# DAC_DAC_50260000h register map
Vendor: Texas Instruments
Peripheral module from a debugger description file (folder AM263X).
Registers are 16-bit, read-write, reset 0x0 unless marked. A register's access mark holds for its fields unless they carry their own. Offsets are as the file gives them; lines under a group give offsets from that group; [hi:lo] are bit positions; {n}, {i} and the like mark numbered series; 'fields as' and 'values as' point back to an identical list; <NAME> marks a mode.

## DAC
0x00 DAC_DACREV ro — DAC Revision Register.
  [7:0] REV — DAC Revision
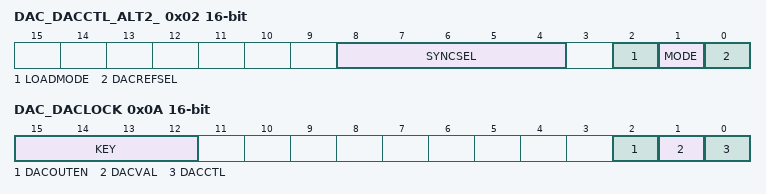
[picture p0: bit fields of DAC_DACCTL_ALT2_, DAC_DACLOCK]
0x02 DAC_DACCTL_ALT2_ — DAC Control Register.
  [8:4] SYNCSEL — DAC EPWMSYNCPER select. Determines which EPWMSYNCPER signal will update the DACVALA register. Where n represents the maximum number of EPWMSYNCPER signals available on the device: 0 EPWM1SYNCPER 1 EPWM2SYNCPER 2 EPWM3SYNCPER ... n-1 EPWMnSYNCPER
  [2] LOADMODE — DACVALA load mode. Determines when the DACVALA register is updated with the value from DACVALS. 0 Load on next SYSCLK 1 Load on next EPWMSYNCPER specified by SYNCSEL
  [1] MODE — DAC gain mode select. Selects the gain mode for the buffered output. The MODE value is only used when DACREFSEL=1 and internal ADC reference mode is selected. 0 Gain is 1 1 Gain is 2
  [0] DACREFSEL — DAC reference select. Selects which voltage references are used by the DAC. 0 VDAC/VSSA are the reference voltages 1 ADC VREFHI/VSSA are the reference voltages
0x04 DAC_DACVALA ro — DAC Value Register - Active.
  [11:0] DACVALA — Active output code currently driven by the DAC
0x06 DAC_DACVALS — DAC Value Register - Shadow.
  [11:0] DACVALS — Shadow output code to be loaded into DACVALA
0x08 DAC_DACOUTEN — DAC Output Enable Register.
  [0] DACOUTEN — DAC output enable 0 DAC output is disabled 1 DAC output is enabled
0x0A DAC_DACLOCK access not given — DAC Lock Register.
  [15:12] KEY rw — Writes to this register succeed only if this field is written with a value of 0xA. Only 16-bit writes will succeed [provided the KEY matches]. Read-modify-writes to individual bits in this register will be ignored.
  [2] DACOUTEN — Lock write-access to the DACOUTEN register. 0 DACOUTEN register is not locked. Write 0 to this bit has no effect. 1 DACOUTEN register is locked. Only a system reset can clear this bit. (access R/W1TS)
  [1] DACVAL — Lock write-access to the DACVALS register. 0 DACVALS register is not locked. Write 0 to this bit has no effect. 1 DACVALS register is locked. Only a system reset can clear this bit. (access R/W1TS)
  [0] DACCTL — Lock write-access to the DACCTL register. 0 DACCTL register is not locked. Write 0 to this bit has no effect. 1 DACCTL register is locked. Only a system reset can clear this bit. (access R/W1TS)
0x0E DAC_DACCONFIG — DAC Configuration Register.
  [15:0] CONFIG — DAC Configuration. This bit field is used for TI internal testing/debugging.
